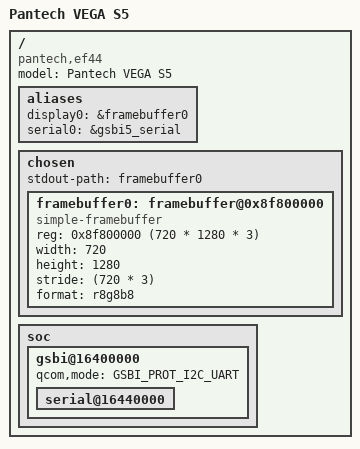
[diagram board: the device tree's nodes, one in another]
// SPDX-License-Identifier: GPL-2.0-only
#include <dt-bindings/input/input.h>

#include "qcom-msm8960.dtsi"

/ {
	model = "Pantech VEGA S5";
	compatible = "pantech,ef44", "qcom,msm8960";

	aliases {
		display0 = &framebuffer0;
		serial0 = &gsbi5_serial;
	};

	chosen {
		stdout-path = "framebuffer0";

		ranges;

		framebuffer0: framebuffer@0x8f800000 {
			compatible = "simple-framebuffer";
			reg = <0x8f800000 (720 * 1280 * 3)>;
			width = <720>;
			height = <1280>;
			stride = <(720 * 3)>;
			format = "r8g8b8";
		};
	};
	
	soc {
		gsbi@16400000 {
			status = "okay";
			qcom,mode = <GSBI_PROT_I2C_UART>;
			serial@16440000 {
				status = "okay";
			};
		};
	};
};
